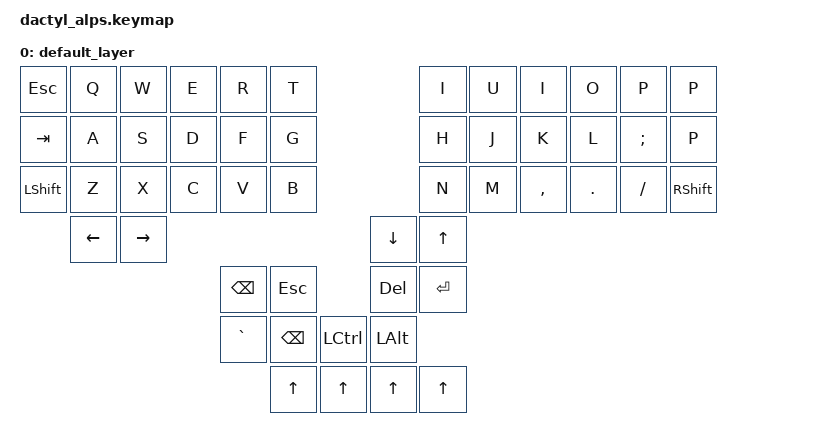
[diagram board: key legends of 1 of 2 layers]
#include <behaviors.dtsi>
#include <dt-bindings/zmk/keys.h>
#include <dt-bindings/zmk/bt.h>
#include <dt-bindings/zmk/outputs.h>
#include <dt-bindings/zmk/ext_power.h>

#define DEFAULT 0
#define MAC     1

#define HYPER(key) LS(LC(LA(LG(key))))
#define MEH(key)   LS(LC(LA(key)))

&sl {
    release-after-ms = <5000>;
};

&kscan0 {
    debounce-press-ms = <30>;
    debounce-release-ms = <30>;
};

/ {
    keymap {
        compatible = "zmk,keymap";

        default_layer {
            bindings = <
     &kp ESC    &kp Q     &kp W    &kp E     &kp R     &kp T                              &kp I     &kp U     &kp I     &kp O     &kp P &kp P
     &kp TAB    &kp A     &kp S    &kp D     &kp F     &kp G                              &kp H     &kp J     &kp K     &kp L     &kp SEMI  &kp P
     &kp LSHIFT &kp Z     &kp X    &kp C     &kp V     &kp B                              &kp N     &kp M     &kp COMMA &kp DOT   &kp FSLH  &kp RSHIFT
                &kp LEFT  &kp RIGHT                                              &kp DOWN  &kp UP
                                         &kp BSPC &kp ESC                  &kp DEL  &kp ENTER
                                             &kp GRAVE  &kp BSPC      &kp LCTRL &kp LALT
                                                    &kp UP &kp UP    &kp UP &kp UP
            >;
        };

        mac_layer  {
            bindings = <
      &kp Q     &kp W    &kp E     &kp R     &kp T                              &kp Y     &kp U     &kp I     &kp O     &kp P
     &kp A     &kp S    &kp D     &kp F     &kp G                              &kp H     &kp J     &kp K     &kp L     &kp SEMI
     &kp Z     &kp X    &kp C     &kp V     &kp B                              &kp N     &kp M     &kp COMMA &kp DOT   &kp FSLH
             &kp LEFT  &kp RIGHT                                              &kp DOWN  &kp UP
                                         &kp BSPC &kp ESC &kp DEL  &kp ENTER  &kp SPACE
                                                    &kp GRAVE   &kp BSPC   &kp LCTRL &kp LALT
            >;
        };

    };
};
